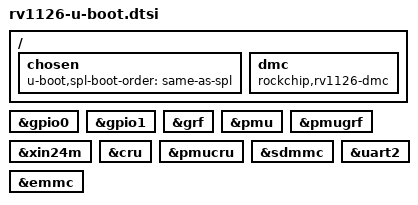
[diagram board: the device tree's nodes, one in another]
// SPDX-License-Identifier: (GPL-2.0+ OR MIT)
/*
 * Copyright (c) 2022 Edgeble AI Technologies Pvt. Ltd.
 */

#include "rockchip-u-boot.dtsi"

/ {
	chosen {
		u-boot,spl-boot-order = \
			"same-as-spl", &emmc, &sdmmc;
	};

	dmc {
		compatible = "rockchip,rv1126-dmc";
		bootph-all;
	};
};

&gpio0 {
	bootph-pre-ram;
};

&gpio1 {
	bootph-pre-ram;
};

&grf {
	bootph-pre-ram;
};

&pmu {
	bootph-pre-ram;
};

&pmugrf {
	bootph-pre-ram;
};

&xin24m {
	bootph-pre-ram;
};

&cru {
	bootph-pre-ram;
};

&pmucru {
	bootph-pre-ram;
};

&sdmmc {
	bootph-pre-ram;
};

&emmc {
	bootph-pre-ram;
};

&uart2 {
	bootph-pre-ram;
};
